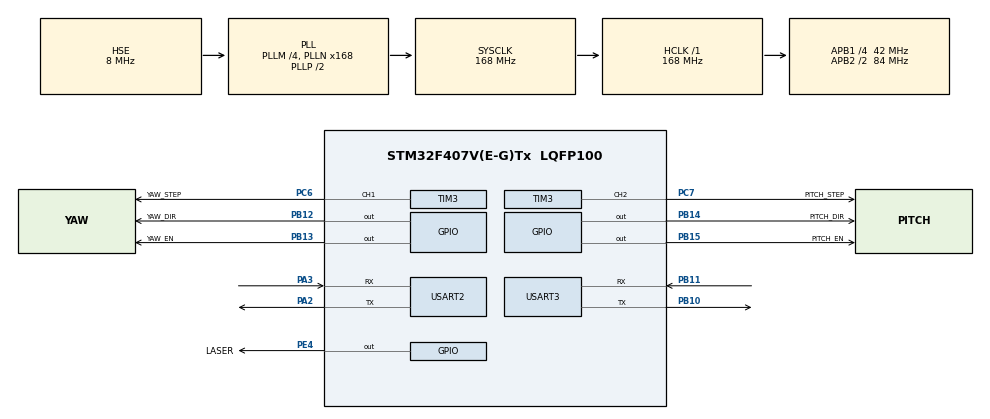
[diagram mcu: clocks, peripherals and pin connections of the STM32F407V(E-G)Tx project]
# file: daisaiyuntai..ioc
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Mcu.Family=STM32F4
Mcu.Name=STM32F407V(E-G)Tx
Mcu.Package=LQFP100
NVIC.PriorityGroup=NVIC_PRIORITYGROUP_4
NVIC.TIM1_UP_TIM10_IRQn=true\:0\:0\:true\:false\:true\:true\:true\:true
PA13.Mode=Serial_Wire
PA13.Signal=SYS_JTMS-SWDIO
PA14.Mode=Serial_Wire
PA14.Signal=SYS_JTCK-SWCLK
PA2.Mode=Asynchronous
PA2.Signal=USART2_TX
PA3.Mode=Asynchronous
PA3.Signal=USART2_RX
PB10.Mode=Asynchronous
PB10.Signal=USART3_TX
PB11.Mode=Asynchronous
PB11.Signal=USART3_RX
PB12.GPIO_Label=YAW_DIR
PB12.GPIO_Speed=GPIO_SPEED_FREQ_HIGH
PB12.PinState=GPIO_PIN_RESET
PB12.Signal=GPIO_Output
PB13.GPIO_Label=YAW_EN
PB13.GPIO_Speed=GPIO_SPEED_FREQ_HIGH
PB13.PinState=GPIO_PIN_SET
PB13.Signal=GPIO_Output
PB14.GPIO_Label=PITCH_DIR
PB14.GPIO_Speed=GPIO_SPEED_FREQ_HIGH
PB14.PinState=GPIO_PIN_RESET
PB14.Signal=GPIO_Output
PB15.GPIO_Label=PITCH_EN
PB15.GPIO_Speed=GPIO_SPEED_FREQ_HIGH
PB15.PinState=GPIO_PIN_SET
PB15.Signal=GPIO_Output
PC6.GPIO_Label=YAW_STEP
PC6.Signal=S_TIM3_CH1
PC7.GPIO_Label=PITCH_STEP
PC7.Signal=S_TIM3_CH2
PE4.GPIO_Label=LASER
PE4.GPIO_Speed=GPIO_SPEED_FREQ_HIGH
PE4.PinState=GPIO_PIN_RESET
PE4.Signal=GPIO_Output
PH0-OSC_IN.Mode=HSE-External-Oscillator
PH0-OSC_IN.Signal=RCC_OSC_IN
PH1-OSC_OUT.Mode=HSE-External-Oscillator
PH1-OSC_OUT.Signal=RCC_OSC_OUT
ProjectManager.HeapSize=0x200
ProjectManager.StackSize=0x400
ProjectManager.TargetToolchain=MDK-ARM V5.32
RCC.48MHZClocksFreq_Value=84000000
RCC.AHBFreq_Value=168000000
RCC.APB1CLKDivider=RCC_HCLK_DIV4
RCC.APB1Freq_Value=42000000
RCC.APB1TimFreq_Value=84000000
RCC.APB2CLKDivider=RCC_HCLK_DIV2
RCC.APB2Freq_Value=84000000
RCC.APB2TimFreq_Value=168000000
RCC.CortexFreq_Value=168000000
RCC.HCLKFreq_Value=168000000
RCC.HSE_VALUE=8000000
RCC.HSI_VALUE=16000000
RCC.LSE_VALUE=32768
RCC.PLLM=4
RCC.PLLN=168
RCC.PLLSourceVirtual=RCC_PLLSOURCE_HSE
RCC.SYSCLKFreq_VALUE=168000000
RCC.SYSCLKSource=RCC_SYSCLKSOURCE_PLLCLK
RCC.VCOOutputFreq_Value=336000000
SH.S_TIM3_CH1.0=TIM3_CH1,PWM Generation1 CH1
SH.S_TIM3_CH2.0=TIM3_CH2,PWM Generation2 CH2
TIM1.AutoReloadPreload=TIM_AUTORELOAD_PRELOAD_ENABLE
TIM1.Period=1000
TIM1.Prescaler=167
TIM3.Channel-PWM\ Generation1\ CH1=TIM_CHANNEL_1
TIM3.Channel-PWM\ Generation2\ CH2=TIM_CHANNEL_2
TIM3.OCFastMode_PWM-PWM\ Generation1\ CH1=TIM_OCFAST_ENABLE
TIM3.OCFastMode_PWM-PWM\ Generation2\ CH2=TIM_OCFAST_ENABLE
TIM3.Period=65535
TIM3.Prescaler=83
USART2.VirtualMode=VM_ASYNC
USART3.VirtualMode=VM_ASYNC
VP_TIM1_VS_ClockSourceINT.Mode=Internal
VP_TIM3_VS_ClockSourceINT.Mode=Internal
board=custom

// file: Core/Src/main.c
/* USER CODE BEGIN Header */
/**
  ******************************************************************************
  * @file           : main.c
  * @brief          : Main program body
  ******************************************************************************
  * @attention
  *
  * Copyright (c) 2026 STMicroelectronics.
  * All rights reserved.
  *
  * This software is licensed under terms that can be found in the LICENSE file
  * in the root directory of this software component.
  * If no LICENSE file comes with this software, it is provided AS-IS.
  *
  ******************************************************************************
  */
/* USER CODE END Header */
#include "main.h"

/* USER CODE BEGIN Includes */
#include "control.h"
/* USER CODE END Includes */

TIM_HandleTypeDef htim1;
TIM_HandleTypeDef htim3;

UART_HandleTypeDef huart2;
UART_HandleTypeDef huart3;

void SystemClock_Config(void);
static void MX_GPIO_Init(void);
static void MX_TIM1_Init(void);
static void MX_TIM3_Init(void);
static void MX_USART2_UART_Init(void);
static void MX_USART3_UART_Init(void);

int main(void)
{

  /* MCU Configuration--------------------------------------------------------*/

  /* Reset of all peripherals, Initializes the Flash interface and the Systick. */
  HAL_Init();

  /* Configure the system clock */
  SystemClock_Config();

  /* Initialize all configured peripherals */
  MX_GPIO_Init();
  MX_TIM1_Init();
  MX_TIM3_Init();
  MX_USART2_UART_Init();
  MX_USART3_UART_Init();
  /* USER CODE BEGIN 2 */
  TMC2209_Init(TMC_MRES_16);
  HAL_TIM_Base_Start_IT(&htim1);
  /* USER CODE END 2 */

  /* Infinite loop */
  while (1)
  {

  }
}

void SystemClock_Config(void)
{
  RCC_OscInitTypeDef RCC_OscInitStruct = {0};
  RCC_ClkInitTypeDef RCC_ClkInitStruct = {0};

  /** Configure the main internal regulator output voltage
  */
  __HAL_RCC_PWR_CLK_ENABLE();
  __HAL_PWR_VOLTAGESCALING_CONFIG(PWR_REGULATOR_VOLTAGE_SCALE1);

  /** Initializes the RCC Oscillators according to the specified parameters
  * in the RCC_OscInitTypeDef structure.
  */
  RCC_OscInitStruct.OscillatorType = RCC_OSCILLATORTYPE_HSE;
  RCC_OscInitStruct.HSEState = RCC_HSE_ON;
  RCC_OscInitStruct.PLL.PLLState = RCC_PLL_ON;
  RCC_OscInitStruct.PLL.PLLSource = RCC_PLLSOURCE_HSE;
  RCC_OscInitStruct.PLL.PLLM = 4;
  RCC_OscInitStruct.PLL.PLLN = 168;
  RCC_OscInitStruct.PLL.PLLP = RCC_PLLP_DIV2;
  RCC_OscInitStruct.PLL.PLLQ = 4;
  if (HAL_RCC_OscConfig(&RCC_OscInitStruct) != HAL_OK)
  {
    Error_Handler();
  }

  /** Initializes the CPU, AHB and APB buses clocks
  */
  RCC_ClkInitStruct.ClockType = RCC_CLOCKTYPE_HCLK|RCC_CLOCKTYPE_SYSCLK
                              |RCC_CLOCKTYPE_PCLK1|RCC_CLOCKTYPE_PCLK2;
  RCC_ClkInitStruct.SYSCLKSource = RCC_SYSCLKSOURCE_PLLCLK;
  RCC_ClkInitStruct.AHBCLKDivider = RCC_SYSCLK_DIV1;
  RCC_ClkInitStruct.APB1CLKDivider = RCC_HCLK_DIV4;
  RCC_ClkInitStruct.APB2CLKDivider = RCC_HCLK_DIV2;

  if (HAL_RCC_ClockConfig(&RCC_ClkInitStruct, FLASH_LATENCY_5) != HAL_OK)
  {
    Error_Handler();
  }
}

static void MX_TIM1_Init(void)
{

  TIM_ClockConfigTypeDef sClockSourceConfig = {0};
  TIM_MasterConfigTypeDef sMasterConfig = {0};

  htim1.Instance = TIM1;
  htim1.Init.Prescaler = 167;
  htim1.Init.CounterMode = TIM_COUNTERMODE_UP;
  htim1.Init.Period = 1000;
  htim1.Init.ClockDivision = TIM_CLOCKDIVISION_DIV1;
  htim1.Init.RepetitionCounter = 0;
  htim1.Init.AutoReloadPreload = TIM_AUTORELOAD_PRELOAD_ENABLE;
  if (HAL_TIM_Base_Init(&htim1) != HAL_OK)
  {
    Error_Handler();
  }
  sClockSourceConfig.ClockSource = TIM_CLOCKSOURCE_INTERNAL;
  if (HAL_TIM_ConfigClockSource(&htim1, &sClockSourceConfig) != HAL_OK)
  {
    Error_Handler();
  }
  sMasterConfig.MasterOutputTrigger = TIM_TRGO_RESET;
  sMasterConfig.MasterSlaveMode = TIM_MASTERSLAVEMODE_DISABLE;
  if (HAL_TIMEx_MasterConfigSynchronization(&htim1, &sMasterConfig) != HAL_OK)
  {
    Error_Handler();
  }

}

static void MX_TIM3_Init(void)
{

  TIM_ClockConfigTypeDef sClockSourceConfig = {0};
  TIM_MasterConfigTypeDef sMasterConfig = {0};
  TIM_OC_InitTypeDef sConfigOC = {0};

  htim3.Instance = TIM3;
  htim3.Init.Prescaler = 83;
  htim3.Init.CounterMode = TIM_COUNTERMODE_UP;
  htim3.Init.Period = 65535;
  htim3.Init.ClockDivision = TIM_CLOCKDIVISION_DIV1;
  htim3.Init.AutoReloadPreload = TIM_AUTORELOAD_PRELOAD_DISABLE;
  if (HAL_TIM_Base_Init(&htim3) != HAL_OK)
  {
    Error_Handler();
  }
  sClockSourceConfig.ClockSource = TIM_CLOCKSOURCE_INTERNAL;
  if (HAL_TIM_ConfigClockSource(&htim3, &sClockSourceConfig) != HAL_OK)
  {
    Error_Handler();
  }
  if (HAL_TIM_PWM_Init(&htim3) != HAL_OK)
  {
    Error_Handler();
  }
  sMasterConfig.MasterOutputTrigger = TIM_TRGO_RESET;
  sMasterConfig.MasterSlaveMode = TIM_MASTERSLAVEMODE_DISABLE;
  if (HAL_TIMEx_MasterConfigSynchronization(&htim3, &sMasterConfig) != HAL_OK)
  {
    Error_Handler();
  }
  sConfigOC.OCMode = TIM_OCMODE_PWM1;
  sConfigOC.Pulse = 0;
  sConfigOC.OCPolarity = TIM_OCPOLARITY_HIGH;
  sConfigOC.OCFastMode = TIM_OCFAST_ENABLE;
  if (HAL_TIM_PWM_ConfigChannel(&htim3, &sConfigOC, TIM_CHANNEL_1) != HAL_OK)
  {
    Error_Handler();
  }
  if (HAL_TIM_PWM_ConfigChannel(&htim3, &sConfigOC, TIM_CHANNEL_2) != HAL_OK)
  {
    Error_Handler();
  }
  HAL_TIM_MspPostInit(&htim3);

}

static void MX_USART2_UART_Init(void)
{

  huart2.Instance = USART2;
  huart2.Init.BaudRate = 115200;
  huart2.Init.WordLength = UART_WORDLENGTH_8B;
  huart2.Init.StopBits = UART_STOPBITS_1;
  huart2.Init.Parity = UART_PARITY_NONE;
  huart2.Init.Mode = UART_MODE_TX_RX;
  huart2.Init.HwFlowCtl = UART_HWCONTROL_NONE;
  huart2.Init.OverSampling = UART_OVERSAMPLING_16;
  if (HAL_UART_Init(&huart2) != HAL_OK)
  {
    Error_Handler();
  }

}

static void MX_USART3_UART_Init(void)
{

  huart3.Instance = USART3;
  huart3.Init.BaudRate = 115200;
  huart3.Init.WordLength = UART_WORDLENGTH_8B;
  huart3.Init.StopBits = UART_STOPBITS_1;
  huart3.Init.Parity = UART_PARITY_NONE;
  huart3.Init.Mode = UART_MODE_TX_RX;
  huart3.Init.HwFlowCtl = UART_HWCONTROL_NONE;
  huart3.Init.OverSampling = UART_OVERSAMPLING_16;
  if (HAL_UART_Init(&huart3) != HAL_OK)
  {
    Error_Handler();
  }

}

static void MX_GPIO_Init(void)
{
  GPIO_InitTypeDef GPIO_InitStruct = {0};

  /* GPIO Ports Clock Enable */
  __HAL_RCC_GPIOE_CLK_ENABLE();
  __HAL_RCC_GPIOH_CLK_ENABLE();
  __HAL_RCC_GPIOA_CLK_ENABLE();
  __HAL_RCC_GPIOB_CLK_ENABLE();
  __HAL_RCC_GPIOC_CLK_ENABLE();

  /*Configure GPIO pin Output Level */
  HAL_GPIO_WritePin(LASER_GPIO_Port, LASER_Pin, GPIO_PIN_RESET);

  /*Configure GPIO pin Output Level */
  HAL_GPIO_WritePin(GPIOB, YAW_DIR_Pin|PITCH_DIR_Pin, GPIO_PIN_RESET);

  /*Configure GPIO pin Output Level */
  HAL_GPIO_WritePin(GPIOB, YAW_EN_Pin|PITCH_EN_Pin, GPIO_PIN_SET);

  /*Configure GPIO pin : LASER_Pin */
  GPIO_InitStruct.Pin = LASER_Pin;
  GPIO_InitStruct.Mode = GPIO_MODE_OUTPUT_PP;
  GPIO_InitStruct.Pull = GPIO_NOPULL;
  GPIO_InitStruct.Speed = GPIO_SPEED_FREQ_HIGH;
  HAL_GPIO_Init(LASER_GPIO_Port, &GPIO_InitStruct);

  /*Configure GPIO pins : YAW_DIR_Pin YAW_EN_Pin PITCH_DIR_Pin PITCH_EN_Pin */
  GPIO_InitStruct.Pin = YAW_DIR_Pin|YAW_EN_Pin|PITCH_DIR_Pin|PITCH_EN_Pin;
  GPIO_InitStruct.Mode = GPIO_MODE_OUTPUT_PP;
  GPIO_InitStruct.Pull = GPIO_NOPULL;
  GPIO_InitStruct.Speed = GPIO_SPEED_FREQ_HIGH;
  HAL_GPIO_Init(GPIOB, &GPIO_InitStruct);

}

/* USER CODE BEGIN 4 */
void HAL_TIM_PeriodElapsedCallback(TIM_HandleTypeDef *htim)
{
  if (htim->Instance == TIM1)
  {
    TMC2209_SpeedRamp_Update();
  }
}
/* USER CODE END 4 */

void Error_Handler(void)
{
  __disable_irq();
  while (1)
  {
  }
}
